# MKL28T7_CORE0 register map
Vendor: Freescale Semiconductor, Inc.; Series: Kinetis_L; File version: 1.6
CPU: CM0PLUS r0p0, little endian, no MPU, no FPU, VTOR, 2 interrupt priority bits
Registers are 32-bit, read-write, reset 0x0 unless marked. A register's access mark holds for its fields unless they carry their own. Offsets are from the block's base; [hi:lo] are bit positions; {n}, {i} and the like mark numbered series.

## GPIOA — General Purpose Input/Output
Base 0x4000F000; register names take the prefix GPIOA_
0x00 PDOR — Port Data Output Register
  [31:0] PDO — Port Data Output
    0=Logic level 0 is driven on pin, provided pin is configured for general-purpose output; 1=Logic level 1 is driven on pin, provided pin is configured for general-purpose output
0x04 PSOR wo — Port Set Output Register
  [31:0] PTSO — Port Set Output
    0=Corresponding bit in PDORn does not change; 1=Corresponding bit in PDORn is set to logic 1
0x08 PCOR wo — Port Clear Output Register
  [31:0] PTCO — Port Clear Output
    0=Corresponding bit in PDORn does not change; 1=Corresponding bit in PDORn is cleared to logic 0
0x0C PTOR wo — Port Toggle Output Register
  [31:0] PTTO — Port Toggle Output
    0=Corresponding bit in PDORn does not change; 1=Corresponding bit in PDORn is set to the inverse of its existing logic state
0x10 PDIR ro — Port Data Input Register
  [31:0] PDI — Port Data Input
    0=Pin logic level is logic 0, or is not configured for use by digital function; 1=Pin logic level is logic 1
0x14 PDDR — Port Data Direction Register
  [31:0] PDD — Port Data Direction
    0=Pin is configured as general-purpose input, for the GPIO function; 1=Pin is configured as general-purpose output, for the GPIO function

## GPIOB — General Purpose Input/Output
Base 0x4000F040; register names take the prefix GPIOB_
Registers as GPIOA.

## GPIOC — General Purpose Input/Output
Base 0x4000F080; register names take the prefix GPIOC_
Registers as GPIOA.

## GPIOD — General Purpose Input/Output
Base 0x4000F0C0; register names take the prefix GPIOD_
Registers as GPIOA.

## GPIOE — General Purpose Input/Output
Base 0x4000F100; register names take the prefix GPIOE_
Registers as GPIOA.

## GPIOM — General Purpose Input/Output
Base 0x4008F000; register names take the prefix GPIOM_
Registers as GPIOA.

## FGPIOA — General Purpose Input/Output
Base 0xF8000000; register names take the prefix FGPIOA_
Registers as GPIOA.

## FGPIOM — General Purpose Input/Output
Base 0xF9000000; register names take the prefix FGPIOM_
Registers as GPIOA.

## SEMA420 — SEMA42
Base 0x4001B000; register names take the prefix SEMA420_
0x00 GATE{x} (x=3,2,1,0,7,6,5,4,11,10,9,8,15,14,13,12; step 0x1) 8-bit
  [3:0] GTFSM — Gate Finite State Machine.
    0=The gate is unlocked (free); {v}=The gate has been locked by processor {v-1} (v=1..15)
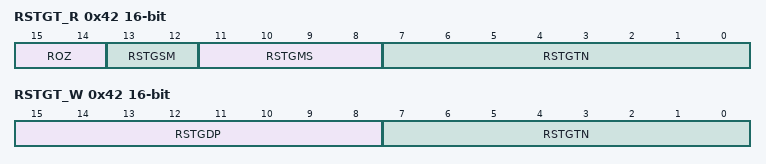
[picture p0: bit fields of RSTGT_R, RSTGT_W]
0x42 RSTGT_R 16-bit ro (SEMA420 view) — Reset Gate Read
  [15:14] ROZ — This field always returns the value 0 when read.
  [13:12] RSTGSM — Reset Gate Finite State Machine
    0=Idle, waiting for the first data pattern write; 1=Waiting for the second data pattern write; 2=The 2-write sequence has completed. Generate the specified gate reset(s). After the reset is performed, this machine returns to the idle (waiting for first data pattern write) state. The "01" state persists for only one clock cycle. Software cannot observe this state.; 3=This state encoding is never used and therefore reserved
  [11:8] RSTGMS — Reset Gate Bus Master
  [7:0] RSTGTN — Reset Gate Number
0x42 RSTGT_W 16-bit wo (SEMA420 view) — Reset Gate Write
  [15:8] RSTGDP — Reset Gate Data Pattern
  [7:0] RSTGTN — Reset Gate Number

## SEMA421 — SEMA42
Base 0x4009B000; register names take the prefix SEMA421_
Registers as SEMA420 (with SEMA420 read as SEMA421).

## DMAMUX0 — DMA channel multiplexor
Base 0x40021000; register names take the prefix DMAMUX0_
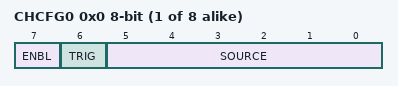
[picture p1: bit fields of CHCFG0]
{0x0+i} CHCFG{i} (i=0..7) 8-bit — Channel Configuration register
  [7] ENBL — DMA Channel Enable
    0=DMA channel is disabled. This mode is primarily used during configuration of the DMAMux. The DMA has separate channel enables/disables, which should be used to disable or reconfigure a DMA channel.; 1=DMA channel is enabled
  [6] TRIG — DMA Channel Trigger Enable
    0=Triggering is disabled. If triggering is disabled and ENBL is set, the DMA Channel will simply route the specified source to the DMA channel. (Normal mode); 1=Triggering is enabled. If triggering is enabled and ENBL is set, the DMAMUX is in Periodic Trigger mode.
  [5:0] SOURCE — DMA Channel Source (Slot)

## DMAMUX1 — DMA channel multiplexor
Base 0x400A1000; register names take the prefix DMAMUX1_
Registers as DMAMUX0.

## Notices in the file
Redistribution and use in source and binary forms, with or without modification,
are permitted provided that the following conditions are met:
o Redistributions of source code must retain the above copyright notice, this list
of conditions and the following disclaimer.
o Redistributions in binary form must reproduce the above copyright notice, this
list of conditions and the following disclaimer in the documentation and/or
other materials provided with the distribution.
o Neither the name of Freescale Semiconductor, Inc. nor the names of its
contributors may be used to endorse or promote products derived from this
software without specific prior written permission.
THIS SOFTWARE IS PROVIDED BY THE COPYRIGHT HOLDERS AND CONTRIBUTORS "AS IS" AND
ANY EXPRESS OR IMPLIED WARRANTIES, INCLUDING, BUT NOT LIMITED TO, THE IMPLIED
WARRANTIES OF MERCHANTABILITY AND FITNESS FOR A PARTICULAR PURPOSE ARE
DISCLAIMED. IN NO EVENT SHALL THE COPYRIGHT HOLDER OR CONTRIBUTORS BE LIABLE FOR
ANY DIRECT, INDIRECT, INCIDENTAL, SPECIAL, EXEMPLARY, OR CONSEQUENTIAL DAMAGES
(INCLUDING, BUT NOT LIMITED TO, PROCUREMENT OF SUBSTITUTE GOODS OR SERVICES;
LOSS OF USE, DATA, OR PROFITS; OR BUSINESS INTERRUPTION) HOWEVER CAUSED AND ON
ANY THEORY OF LIABILITY, WHETHER IN CONTRACT, STRICT LIABILITY, OR TORT
(INCLUDING NEGLIGENCE OR OTHERWISE) ARISING IN ANY WAY OUT OF THE USE OF THIS
SOFTWARE, EVEN IF ADVISED OF THE POSSIBILITY OF SUCH DAMAGE.
